# BlueNRG1 register map
Vendor: STMicroelectronics; Series: BlueNRG1; File version: 2.2.1
CPU: CM0 r0p0, little endian, no MPU, no FPU, 2 interrupt priority bits
Registers are 32-bit, read-write, reset 0x0 unless marked. A register's access mark holds for its fields unless they carry their own. Offsets are from the block's base; [hi:lo] are bit positions; 'fields as' and 'values as' point back to an identical list.

## DMA_CH0 — DMA channel
Base 0xA0000008
Same registers: DMA_CH1 0xA000001C, DMA_CH2 0xA0000030, DMA_CH3 0xA0000044, DMA_CH4 0xA0000058, DMA_CH5 0xA000006C, DMA_CH6 0xA0000080, DMA_CH7 0xA0000094
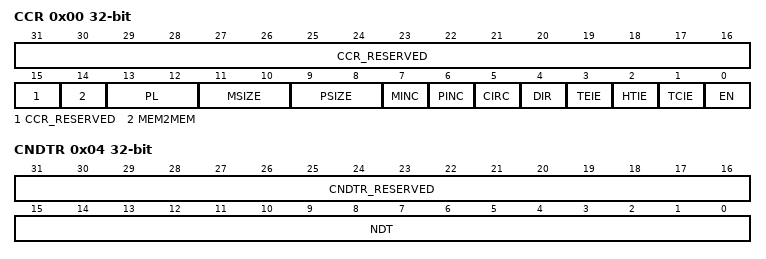
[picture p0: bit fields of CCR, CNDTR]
0x00 CCR (reset mask 0xFFFF) — DMA channel configuration register
  [31:15] CCR_RESERVED ro — CCR not used bitfield.
  [14] MEM2MEM — Memory to memory mode.<ul><li>0: Memory to memory mode disabled.</li><li>0: Memory to memory mode enabled.</li></ul>
  [13:12] PL — Channel priority level.<ul><li>00b: Low priority.</li><li>01b: Medium priority.</li><li>10b: High priority.</li><li>11b: Very high priority.</li></ul>
    0=LOW (Low priority); 1=MEDIUM (Medium priority); 2=HIGH (High priority); 3=VERY_HIGH (Very high priority)
  [11:10] MSIZE — Memory size.<ul><li>00b: Size 8 bits.</li><li>01b: Size 16 bits.</li><li>10b: Size 32 bits.</li></ul>
    0=SIZE8BIT (Size 8 bits); 1=SIZE16BIT (Size 16 bits); 2=SIZE32BIT (Size 32 bits)
  [9:8] PSIZE — Peripheral size.<ul><li>00b: Size 8 bits.</li><li>01b: Size 16 bits.</li><li>10b: Size 32 bits.</li></ul>
    values as MSIZE
  [7] MINC — Memory increment mode.<ul><li>0: Memory increment disabled.</li><li>1: Memory increment enabled.</li></ul>
    0=DISABLE (Memory increment disable); 1=ENABLE (Memory increment enable)
  [6] PINC — Peripheral increment mode.<ul><li>0: Peripheral increment disabled.</li><li>1: Peripheral increment enabled.</li></ul>
    0=DISABLE (Peripheral increment disable); 1=ENABLE (Peripheral increment enable)
  [5] CIRC — Circular mode.<ul><li>0: Circular mode disabled.</li><li>1: Circular mode enabled.</li></ul>
    0=DISABLE (Circular mode disable); 1=ENABLE (Circular mode enable)
  [4] DIR — Data transfer direction.<ul><li>0: Read from peripheral.</li><li>1: Read from memory.</li></ul>
    0=FROM_PERIPHERAL (Read from peripheral); 1=FROM_MEMORY (Read from memory)
  [3] TEIE — Transfer error interrupt enable.<ul><li>0: TE interrupt disabled.</li><li>1: TE interrupt enabled.</li></ul>
    0=DISABLE (Interrupt source disable); 1=ENABLE (Interrupt source enable)
  [2] HTIE — Half transfer interrupt enable.<ul><li>0: HT interrupt disabled.</li><li>1: HT interrupt enabled.</li></ul>
    values as TEIE
  [1] TCIE — Transfer complete interrupt enable.<ul><li>0: TC interrupt disabled.</li><li>1: TC interrupt enabled.</li></ul>
    values as TEIE
  [0] EN — DMA channel enable.<ul><li>0: DMA channel disabled.</li><li>1: DMA channel enabled.</li></ul>
    0=DISABLE (DMA channel disable); 1=ENABLE (DMA channel enable)
0x04 CNDTR (reset mask 0xFFFF) — DMA channel number of data register.
  [31:16] CNDTR_RESERVED ro — CNDTR not used bitfield.
  [15:0] NDT — Number of data to be transferred (0 up to 65535). This register can only be written when the channel is disabled. Once the channel is enabled, this register is read-only, indicating the remaining bytes to be transmitted. This register decrements after each DMA transfer. Once the transfer is completed, this register can either stay at zero or be reloaded automatically by the value previously programmed if the channel is configured in auto-reload mode. If this register is zero, no transaction can be served whether the channel is enabled or not.
0x08 CPAR — DMA channel peripheral address register
  [31:0] PA — Base address of the peripheral data register from/to which the data will be read/written. When PSIZE is 01 (16-bit), the PA[0] bit is ignored. Access is automatically aligned to a halfword address. When PSIZE is 10 (32-bit), PA[1:0] are ignored. Access is automatically aligned to a word address.
0x0C CMAR — DMA channel memory address register
  [31:0] MA — Base address of the memory area from/to which the data will be read/written. When MSIZE is 01 (16-bit), the MA[0] bit is ignored. Access is automatically aligned to a halfword address. When MSIZE is 10 (32-bit), MA[1:0] are ignored. Access is automatically aligned to a word address.
